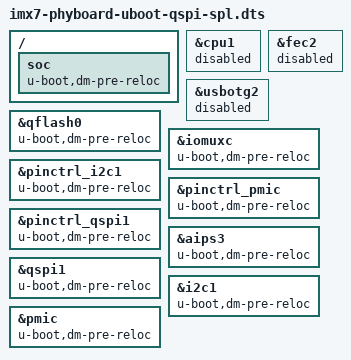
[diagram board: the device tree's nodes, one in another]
// SPDX-License-Identifier: GPL-2.0-or-later
/* Copyright (C) 2015-2021 PHYTEC America, LLC */

/dts-v1/;

#include "imx7-phycore-som.dtsi"	/* SOM */
#include "imx7-pba-c-09.dtsi"		/* Carrier board */
#include "imx7-peb-d-rpi.dtsi"		/* PEB-D-RPI module */

/* No second core, ENET2, USB_OTG2 on i.MX7 Solo */
&cpu1 {
	status = "disabled";
};

&fec2 {
	status = "disabled";
};

&usbotg2 {
	status = "disabled";
};

/* SPL device tree nodes */

&qflash0 {
	u-boot,dm-pre-reloc;
};

&iomuxc {
	u-boot,dm-pre-reloc;
};

&pinctrl_i2c1 {
	u-boot,dm-pre-reloc;
};

&pinctrl_pmic {
	u-boot,dm-pre-reloc;
};

&pinctrl_qspi1 {
	u-boot,dm-pre-reloc;
};

/ {
	soc {
		u-boot,dm-pre-reloc;
	};
};

&aips3 {
	u-boot,dm-pre-reloc;
};

&qspi1 {
	u-boot,dm-pre-reloc;
};

&i2c1 {
	u-boot,dm-pre-reloc;
};

&pmic {
	u-boot,dm-pre-reloc;
};
